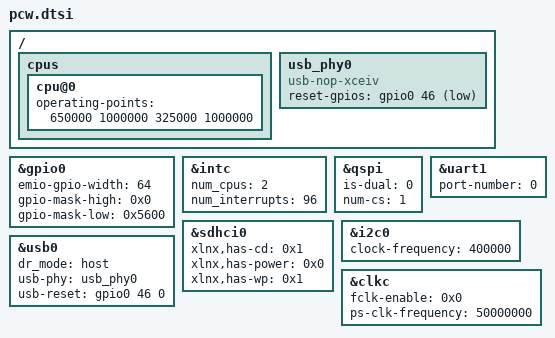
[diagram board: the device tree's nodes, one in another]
/*
 * CAUTION: This file is automatically generated by Xilinx.
 * Version: HSI 2017.2
 * Today is: Sun Jul  9 01:38:35 2017
*/


/ {
	cpus {
		cpu@0 {
			operating-points = <650000 1000000 325000 1000000>;
		};
	};

    usb_phy0: usb_phy0 {
        #phy-cells = <0>;
        compatible = "usb-nop-xceiv";
        reset-gpios = <&gpio0 46 1>;
    };
};
&gpio0 {
	emio-gpio-width = <64>;
	gpio-mask-high = <0x0>;
	gpio-mask-low = <0x5600>;
};
&intc {
	num_cpus = <2>;
	num_interrupts = <96>;
};
&qspi {
	is-dual = <0>;
	num-cs = <1>;
	status = "okay";
};
&sdhci0 {
	status = "okay";
	xlnx,has-cd = <0x1>;
	xlnx,has-power = <0x0>;
	xlnx,has-wp = <0x1>;
};
&uart1 {
	device_type = "serial";
	port-number = <0>;
	status = "okay";
};
&i2c0 {
    status = "okay";
    clock-frequency = <400000>;
};
&usb0 {
	dr_mode = "host";
    usb-phy = <&usb_phy0>;
	status = "okay";
	usb-reset = <&gpio0 46 0>;
};
&clkc {
	fclk-enable = <0x0>;
	ps-clk-frequency = <50000000>;
};
